AUTOSAR XML (schema 00047)
# (C) 2021 HYUNDAI AUTOEVER Corp.
package /Csm/ClientServerInterfaces
  13 x client server interface, all with is-service=true:
    CallbackNotification  # Interface for the callback notification.
      operation CallbackNotification  # Notifies the application with a return value that the job has finished.
        arg result: type=Csm_ResultType, direction=IN  # Return value that shall be returned to the application
    CsmDecryptAES_ECB_DecryptAES_ECB  # Synchronous processing interface to execute the decryption.
      operation Decrypt: possible-error=[CsmDecryptAES_ECB_DecryptAES_ECB/CSM_E_BUSY, CsmDecryptAES_ECB_DecryptAES_ECB/CSM_E_KEY_EMPTY, CsmDecryptAES_ECB_DecryptAES_ECB/CSM_E_KEY_NOT_VALID, CsmDecryptAES_ECB_DecryptAES_ECB/CSM_E_KEY_SIZE_MISMATCH, CsmDecryptAES_ECB_DecryptAES_ECB/CSM_E_SMALL_BUFFER, CsmDecryptAES_ECB_DecryptAES_ECB/E_NOT_OK, CsmDecryptAES_ECB_DecryptAES_ECB/E_OK]  # Streaming approach of the decryption.
        5 x arg:
          mode: type=Crypto_OperationModeType, direction=IN  # indicates which operation mode(s) to perform
          dataBuffer: type=Csm_ConstDataPtr, direction=IN  # Contains the data to be decrypted.
          dataLength: type=uint32, direction=IN  # Contains the length in bytes of the data to be decrypted.
          resultBuffer: type=uint8, direction=OUT  # Contains the data of the decrypted plaintext.
          resultLength: type=uint32, direction=INOUT  # Contains the length in bytes of the decrypted plaintext.
      7 x error:
        CSM_E_BUSY: error-code=2  # Request failed, service is still busy.
        CSM_E_KEY_EMPTY: error-code=13  # The service request failed because of uninitialized source key element.
        CSM_E_KEY_NOT_VALID: error-code=9  # Request failed, the key is not valid.
        CSM_E_KEY_SIZE_MISMATCH: error-code=10  # Request failed because the key element is not partially accessible and the provided key element length is too short or too long for that key element.
        CSM_E_SMALL_BUFFER: error-code=3  # The provided buffer is too small to store the result.
        E_NOT_OK: error-code=1  # Operation failed
        E_OK: error-code=0  # Operation successful
    CsmEncryptAES_ECB_EncryptAES_ECB  # Synchronous processing interface to execute the encryption.
      operation Encrypt: possible-error=[CsmEncryptAES_ECB_EncryptAES_ECB/CSM_E_BUSY, CsmEncryptAES_ECB_EncryptAES_ECB/CSM_E_KEY_EMPTY, CsmEncryptAES_ECB_EncryptAES_ECB/CSM_E_KEY_NOT_VALID, CsmEncryptAES_ECB_EncryptAES_ECB/CSM_E_KEY_SIZE_MISMATCH, CsmEncryptAES_ECB_EncryptAES_ECB/CSM_E_SMALL_BUFFER, CsmEncryptAES_ECB_EncryptAES_ECB/E_NOT_OK, CsmEncryptAES_ECB_EncryptAES_ECB/E_OK]  # Encrypts the given data and store the ciphertext in the memory location pointed by the result pointer.
        5 x arg:
          mode: type=Crypto_OperationModeType, direction=IN  # indicates which operation mode(s) to perform
          dataBuffer: type=Csm_ConstDataPtr, direction=IN  # Contains the data to be encrypted.
          dataLength: type=uint32, direction=IN  # Contains the length in bytes of the data to be encrypted.
          result: type=uint8, direction=OUT  # Contains the data of the cipher.
          resultLength: type=uint32, direction=INOUT  # Contains the length in bytes of the cipher.
      7 x error:
        CSM_E_BUSY: error-code=2  # Request failed, service is still busy.
        CSM_E_KEY_EMPTY: error-code=13  # The service request failed because of uninitialized source key element.
        CSM_E_KEY_NOT_VALID: error-code=9  # Request failed, the key is not valid.
        CSM_E_KEY_SIZE_MISMATCH: error-code=10  # Request failed because the key element is not partially accessible and the provided key element length is too short or too long for that key element.
        CSM_E_SMALL_BUFFER: error-code=3  # The provided buffer is too small to store the result.
        E_NOT_OK: error-code=1  # Operation failed
        E_OK: error-code=0  # Operation successful
    CsmHash_CsmHashConfig  # Synchronous processing interface to execute the hash calculation.
      operation Hash: possible-error=[CsmHash_CsmHashConfig/CSM_E_BUSY, CsmHash_CsmHashConfig/CSM_E_SMALL_BUFFER, CsmHash_CsmHashConfig/E_NOT_OK, CsmHash_CsmHashConfig/E_OK]  # Streaming approach of the hash calculation.
        5 x arg:
          mode: type=Crypto_OperationModeType, direction=IN  # indicates which operation mode(s) to perform
          dataBuffer: type=Csm_ConstDataPtr, direction=IN  # Contains the data to be hashed.
          dataLength: type=uint32, direction=IN  # Contains the length in bytes of the data to be hashed.
          resultBuffer: type=uint8, direction=OUT  # Contains the data of the hash.
          resultLength: type=uint32, direction=INOUT  # Contains the length in bytes of the hash.
      4 x error:
        CSM_E_BUSY: error-code=2  # Request failed, service is still busy.
        CSM_E_SMALL_BUFFER: error-code=3  # The provided buffer is too small to store the result.
        E_NOT_OK: error-code=1  # Operation failed
        E_OK: error-code=0  # Operation successful
    CsmKeyManagement_Dummy  # Interface to execute the key management functions.
      11 x operation:
        KeyCopy: possible-error=[CsmKeyManagement_Dummy/CSM_E_BUSY, CsmKeyManagement_Dummy/CSM_E_KEY_EMPTY, CsmKeyManagement_Dummy/CSM_E_KEY_NOT_AVAILABLE, CsmKeyManagement_Dummy/CSM_E_KEY_READ_FAIL, CsmKeyManagement_Dummy/CSM_E_KEY_SIZE_MISMATCH, CsmKeyManagement_Dummy/CSM_E_KEY_WRITE_FAIL, CsmKeyManagement_Dummy/E_NOT_OK, CsmKeyManagement_Dummy/E_OK]  # This function shall copy all key elements from the source key to a target key.
          arg targetKeyId: type=uint32, direction=IN  # Holds the identifier of the key whose key element shall be the destination element.
        KeyDerive: possible-error=[CsmKeyManagement_Dummy/CSM_E_BUSY, CsmKeyManagement_Dummy/CSM_E_KEY_EMPTY, CsmKeyManagement_Dummy/CSM_E_KEY_READ_FAIL, CsmKeyManagement_Dummy/CSM_E_KEY_SIZE_MISMATCH, CsmKeyManagement_Dummy/CSM_E_KEY_WRITE_FAIL, CsmKeyManagement_Dummy/E_NOT_OK, CsmKeyManagement_Dummy/E_OK]  # Derives a new key by using the key elements in the given key. The given key contains the key elements for the password and salt. The derived key is stored in the key element with the id 1 of the key identified by targetCryptoKeyId.
          arg targetKeyId: type=uint32, direction=IN  # Holds the identifier of the key which is used to store the derived key.
        KeyElementCopy: possible-error=[CsmKeyManagement_Dummy/CSM_E_BUSY, CsmKeyManagement_Dummy/CSM_E_KEY_EMPTY, CsmKeyManagement_Dummy/CSM_E_KEY_NOT_AVAILABLE, CsmKeyManagement_Dummy/CSM_E_KEY_READ_FAIL, CsmKeyManagement_Dummy/CSM_E_KEY_SIZE_MISMATCH, CsmKeyManagement_Dummy/CSM_E_KEY_WRITE_FAIL, CsmKeyManagement_Dummy/E_NOT_OK, CsmKeyManagement_Dummy/E_OK]  # This function shall copy a key elements from one key to a target key
          arg keyElementId: type=uint32, direction=IN  # Holds the identifier of the key element which shall be the source for the copy operation.
          arg targetKeyId: type=uint32, direction=IN  # Holds the identifier of the key whose key element shall be the destination element.
          arg targetKeyElementId: type=uint32, direction=IN  # Holds the identifier of the key element which shall be the destination for the copy operation.
        KeyElementCopyPartial: possible-error=[CsmKeyManagement_Dummy/CSM_E_BUSY, CsmKeyManagement_Dummy/CSM_E_KEY_EMPTY, CsmKeyManagement_Dummy/CSM_E_KEY_NOT_AVAILABLE, CsmKeyManagement_Dummy/CSM_E_KEY_READ_FAIL, CsmKeyManagement_Dummy/CSM_E_KEY_SIZE_MISMATCH, CsmKeyManagement_Dummy/CSM_E_KEY_WRITE_FAIL, CsmKeyManagement_Dummy/E_NOT_OK, CsmKeyManagement_Dummy/E_OK]  # This function shall copy parts of a a key elements from one key to parts of a target key element of a target key.
          6 x arg, all with type=uint32, direction=IN:
            keyElementId  # Holds the identifier of the key element which shall be the source for the copy operation.
            keyElementSourceOffset  # This is the offset of the source key element indicating the start index of the copy operation.
            keyElementTargetOffset  # This is the offset of the destination key element indicating the start index of the copy operation.
            keyElementCopyLength  # Specifies the number of bytes that shall be copied.
            targetKeyId  # Holds the identifier of the key whose key element shall be the destination element.
            targetKeyElementId  # Holds the identifier of the key element which shall be the destination for the copy operation.
        KeyElementGet: possible-error=[CsmKeyManagement_Dummy/CSM_E_BUSY, CsmKeyManagement_Dummy/CSM_E_KEY_EMPTY, CsmKeyManagement_Dummy/CSM_E_KEY_NOT_AVAILABLE, CsmKeyManagement_Dummy/CSM_E_KEY_READ_FAIL, CsmKeyManagement_Dummy/CSM_E_SMALL_BUFFER, CsmKeyManagement_Dummy/E_NOT_OK, CsmKeyManagement_Dummy/E_OK]  # Retrieves the key element bytes from a specific key element of the key and stores the key element in the provided buffer.
          arg keyElementId: type=uint32, direction=IN  # Holds the identifier of the key element to be read.
          arg keyPtr: type=uint8, direction=OUT  # Holds the data to the key element bytes to be written.
          arg keyLength: type=uint32, direction=INOUT  # Contains the number of key element bytes.
        KeyElementSet: possible-error=[CsmKeyManagement_Dummy/CSM_E_BUSY, CsmKeyManagement_Dummy/CSM_E_KEY_NOT_AVAILABLE, CsmKeyManagement_Dummy/CSM_E_KEY_SIZE_MISMATCH, CsmKeyManagement_Dummy/CSM_E_KEY_WRITE_FAIL, CsmKeyManagement_Dummy/E_NOT_OK, CsmKeyManagement_Dummy/E_OK]  # Sets the given key element bytes to the key.
          arg keyElementId: type=uint32, direction=IN  # Holds the identifier of the key element to be written.
          arg keyPtr: type=Csm_ConstDataPtr, direction=IN  # Holds the data to the key element bytes to be processed.
          arg keyLength: type=uint32, direction=IN  # Contains the number of key element bytes.
        KeyExchangeCalcPubVal: possible-error=[CsmKeyManagement_Dummy/CSM_E_BUSY, CsmKeyManagement_Dummy/CSM_E_KEY_EMPTY, CsmKeyManagement_Dummy/CSM_E_SMALL_BUFFER, CsmKeyManagement_Dummy/E_NOT_OK, CsmKeyManagement_Dummy/E_OK]  # Calculates the public value of the current user for the key exchange and stores the public key in the provided buffer
          arg publicValuePtr: type=uint8, direction=OUT  # Holds a pointer to the memory location in which the public value length in bytes is stored. On calling this function, this parameter shall contain the size of the buffer in bytes provided by publicValuePtr. When the request has finished, the actual length of the returned value shall be stored.
          arg publicValueLengthPtr: type=uint32, direction=INOUT  # Contains the pointer to the data where the public value shall be stored.
        KeyExchangeCalcSecret: possible-error=[CsmKeyManagement_Dummy/CSM_E_BUSY, CsmKeyManagement_Dummy/CSM_E_KEY_EMPTY, CsmKeyManagement_Dummy/CSM_E_SMALL_BUFFER, CsmKeyManagement_Dummy/E_NOT_OK, CsmKeyManagement_Dummy/E_OK]  # Calculates the shared secret key for the key exchange with the key material of the key identified by the keyId and the partner public key. The shared secret key is stored as a key element in the same key.
          arg partnerPublicValuePtr: type=Csm_ConstDataPtr, direction=IN  # Holds the pointer to the memory location containing the partner's public value
          arg partnerPublicValueLength: type=uint32, direction=IN  # Contains the number of bytes of the partner pulic value
        KeyGenerate: possible-error=[CsmKeyManagement_Dummy/CSM_E_BUSY, CsmKeyManagement_Dummy/CSM_E_KEY_EMPTY, CsmKeyManagement_Dummy/E_NOT_OK, CsmKeyManagement_Dummy/E_OK]  # Generates new key material and store it in the key identified by keyId.
        KeySetValid: possible-error=[CsmKeyManagement_Dummy/CSM_E_BUSY, CsmKeyManagement_Dummy/E_NOT_OK, CsmKeyManagement_Dummy/E_OK]  # Sets the given key element bytes to the key.
        RandomSeed: possible-error=[CsmKeyManagement_Dummy/CSM_E_BUSY, CsmKeyManagement_Dummy/E_NOT_OK, CsmKeyManagement_Dummy/E_OK]  # Feeds the key element CRYPTO_KE_RANDOM_SEED with a random seed.
          arg seedPtr: type=Csm_ConstDataPtr, direction=IN  # Holds the data which shall be used for the random seed initialization.
          arg seedLength: type=uint32, direction=IN  # Contains the length of the seed in bytes.
      9 x error:
        CSM_E_BUSY: error-code=2  # Request failed, service is still busy.
        CSM_E_KEY_EMPTY: error-code=13  # The service request failed because of uninitialized source key element.
        CSM_E_KEY_NOT_AVAILABLE: error-code=8  # The service request failed because the key is not available.
        CSM_E_KEY_READ_FAIL: error-code=6  # The service request failed because read access was denied.
        CSM_E_KEY_SIZE_MISMATCH: error-code=10  # Request failed because the key element is not partially accessible and the provided key element length is too short or too long for that key element.
        CSM_E_KEY_WRITE_FAIL: error-code=7  # The service request failed because write access was denied.
        CSM_E_SMALL_BUFFER: error-code=3  # The provided buffer is too small to store the result.
        E_NOT_OK: error-code=1  # Operation failed
        E_OK: error-code=0  # Operation successful
    CsmKeyManagement_PBKDF2_Extracted_Key  # Interface to execute the key management functions.
      11 x operation:
        KeyCopy: possible-error=[CsmKeyManagement_PBKDF2_Extracted_Key/CSM_E_BUSY, CsmKeyManagement_PBKDF2_Extracted_Key/CSM_E_KEY_EMPTY, CsmKeyManagement_PBKDF2_Extracted_Key/CSM_E_KEY_NOT_AVAILABLE, CsmKeyManagement_PBKDF2_Extracted_Key/CSM_E_KEY_READ_FAIL, CsmKeyManagement_PBKDF2_Extracted_Key/CSM_E_KEY_SIZE_MISMATCH, CsmKeyManagement_PBKDF2_Extracted_Key/CSM_E_KEY_WRITE_FAIL, CsmKeyManagement_PBKDF2_Extracted_Key/E_NOT_OK, CsmKeyManagement_PBKDF2_Extracted_Key/E_OK]  # This function shall copy all key elements from the source key to a target key.
          arg targetKeyId: type=uint32, direction=IN  # Holds the identifier of the key whose key element shall be the destination element.
        KeyDerive: possible-error=[CsmKeyManagement_PBKDF2_Extracted_Key/CSM_E_BUSY, CsmKeyManagement_PBKDF2_Extracted_Key/CSM_E_KEY_EMPTY, CsmKeyManagement_PBKDF2_Extracted_Key/CSM_E_KEY_READ_FAIL, CsmKeyManagement_PBKDF2_Extracted_Key/CSM_E_KEY_SIZE_MISMATCH, CsmKeyManagement_PBKDF2_Extracted_Key/CSM_E_KEY_WRITE_FAIL, CsmKeyManagement_PBKDF2_Extracted_Key/E_NOT_OK, CsmKeyManagement_PBKDF2_Extracted_Key/E_OK]  # Derives a new key by using the key elements in the given key. The given key contains the key elements for the password and salt. The derived key is stored in the key element with the id 1 of the key identified by targetCryptoKeyId.
          arg targetKeyId: type=uint32, direction=IN  # Holds the identifier of the key which is used to store the derived key.
        KeyElementCopy: possible-error=[CsmKeyManagement_PBKDF2_Extracted_Key/CSM_E_BUSY, CsmKeyManagement_PBKDF2_Extracted_Key/CSM_E_KEY_EMPTY, CsmKeyManagement_PBKDF2_Extracted_Key/CSM_E_KEY_NOT_AVAILABLE, CsmKeyManagement_PBKDF2_Extracted_Key/CSM_E_KEY_READ_FAIL, CsmKeyManagement_PBKDF2_Extracted_Key/CSM_E_KEY_SIZE_MISMATCH, CsmKeyManagement_PBKDF2_Extracted_Key/CSM_E_KEY_WRITE_FAIL, CsmKeyManagement_PBKDF2_Extracted_Key/E_NOT_OK, CsmKeyManagement_PBKDF2_Extracted_Key/E_OK]  # This function shall copy a key elements from one key to a target key
          arg keyElementId: type=uint32, direction=IN  # Holds the identifier of the key element which shall be the source for the copy operation.
          arg targetKeyId: type=uint32, direction=IN  # Holds the identifier of the key whose key element shall be the destination element.
          arg targetKeyElementId: type=uint32, direction=IN  # Holds the identifier of the key element which shall be the destination for the copy operation.
        KeyElementCopyPartial: possible-error=[CsmKeyManagement_PBKDF2_Extracted_Key/CSM_E_BUSY, CsmKeyManagement_PBKDF2_Extracted_Key/CSM_E_KEY_EMPTY, CsmKeyManagement_PBKDF2_Extracted_Key/CSM_E_KEY_NOT_AVAILABLE, CsmKeyManagement_PBKDF2_Extracted_Key/CSM_E_KEY_READ_FAIL, CsmKeyManagement_PBKDF2_Extracted_Key/CSM_E_KEY_SIZE_MISMATCH, CsmKeyManagement_PBKDF2_Extracted_Key/CSM_E_KEY_WRITE_FAIL, CsmKeyManagement_PBKDF2_Extracted_Key/E_NOT_OK, CsmKeyManagement_PBKDF2_Extracted_Key/E_OK]  # This function shall copy parts of a a key elements from one key to parts of a target key element of a target key.
          6 x arg, all with type=uint32, direction=IN:
            keyElementId  # Holds the identifier of the key element which shall be the source for the copy operation.
            keyElementSourceOffset  # This is the offset of the source key element indicating the start index of the copy operation.
            keyElementTargetOffset  # This is the offset of the destination key element indicating the start index of the copy operation.
            keyElementCopyLength  # Specifies the number of bytes that shall be copied.
            targetKeyId  # Holds the identifier of the key whose key element shall be the destination element.
            targetKeyElementId  # Holds the identifier of the key element which shall be the destination for the copy operation.
        KeyElementGet: possible-error=[CsmKeyManagement_PBKDF2_Extracted_Key/CSM_E_BUSY, CsmKeyManagement_PBKDF2_Extracted_Key/CSM_E_KEY_EMPTY, CsmKeyManagement_PBKDF2_Extracted_Key/CSM_E_KEY_NOT_AVAILABLE, CsmKeyManagement_PBKDF2_Extracted_Key/CSM_E_KEY_READ_FAIL, CsmKeyManagement_PBKDF2_Extracted_Key/CSM_E_SMALL_BUFFER, CsmKeyManagement_PBKDF2_Extracted_Key/E_NOT_OK, CsmKeyManagement_PBKDF2_Extracted_Key/E_OK]  # Retrieves the key element bytes from a specific key element of the key and stores the key element in the provided buffer.
          arg keyElementId: type=uint32, direction=IN  # Holds the identifier of the key element to be read.
          arg keyPtr: type=uint8, direction=OUT  # Holds the data to the key element bytes to be written.
          arg keyLength: type=uint32, direction=INOUT  # Contains the number of key element bytes.
        KeyElementSet: possible-error=[CsmKeyManagement_PBKDF2_Extracted_Key/CSM_E_BUSY, CsmKeyManagement_PBKDF2_Extracted_Key/CSM_E_KEY_NOT_AVAILABLE, CsmKeyManagement_PBKDF2_Extracted_Key/CSM_E_KEY_SIZE_MISMATCH, CsmKeyManagement_PBKDF2_Extracted_Key/CSM_E_KEY_WRITE_FAIL, CsmKeyManagement_PBKDF2_Extracted_Key/E_NOT_OK, CsmKeyManagement_PBKDF2_Extracted_Key/E_OK]  # Sets the given key element bytes to the key.
          arg keyElementId: type=uint32, direction=IN  # Holds the identifier of the key element to be written.
          arg keyPtr: type=Csm_ConstDataPtr, direction=IN  # Holds the data to the key element bytes to be processed.
          arg keyLength: type=uint32, direction=IN  # Contains the number of key element bytes.
        KeyExchangeCalcPubVal: possible-error=[CsmKeyManagement_PBKDF2_Extracted_Key/CSM_E_BUSY, CsmKeyManagement_PBKDF2_Extracted_Key/CSM_E_KEY_EMPTY, CsmKeyManagement_PBKDF2_Extracted_Key/CSM_E_SMALL_BUFFER, CsmKeyManagement_PBKDF2_Extracted_Key/E_NOT_OK, CsmKeyManagement_PBKDF2_Extracted_Key/E_OK]  # Calculates the public value of the current user for the key exchange and stores the public key in the provided buffer
          arg publicValuePtr: type=uint8, direction=OUT  # Holds a pointer to the memory location in which the public value length in bytes is stored. On calling this function, this parameter shall contain the size of the buffer in bytes provided by publicValuePtr. When the request has finished, the actual length of the returned value shall be stored.
          arg publicValueLengthPtr: type=uint32, direction=INOUT  # Contains the pointer to the data where the public value shall be stored.
        KeyExchangeCalcSecret: possible-error=[CsmKeyManagement_PBKDF2_Extracted_Key/CSM_E_BUSY, CsmKeyManagement_PBKDF2_Extracted_Key/CSM_E_KEY_EMPTY, CsmKeyManagement_PBKDF2_Extracted_Key/CSM_E_SMALL_BUFFER, CsmKeyManagement_PBKDF2_Extracted_Key/E_NOT_OK, CsmKeyManagement_PBKDF2_Extracted_Key/E_OK]  # Calculates the shared secret key for the key exchange with the key material of the key identified by the keyId and the partner public key. The shared secret key is stored as a key element in the same key.
          arg partnerPublicValuePtr: type=Csm_ConstDataPtr, direction=IN  # Holds the pointer to the memory location containing the partner's public value
          arg partnerPublicValueLength: type=uint32, direction=IN  # Contains the number of bytes of the partner pulic value
        KeyGenerate: possible-error=[CsmKeyManagement_PBKDF2_Extracted_Key/CSM_E_BUSY, CsmKeyManagement_PBKDF2_Extracted_Key/CSM_E_KEY_EMPTY, CsmKeyManagement_PBKDF2_Extracted_Key/E_NOT_OK, CsmKeyManagement_PBKDF2_Extracted_Key/E_OK]  # Generates new key material and store it in the key identified by keyId.
        KeySetValid: possible-error=[CsmKeyManagement_PBKDF2_Extracted_Key/CSM_E_BUSY, CsmKeyManagement_PBKDF2_Extracted_Key/E_NOT_OK, CsmKeyManagement_PBKDF2_Extracted_Key/E_OK]  # Sets the given key element bytes to the key.
        RandomSeed: possible-error=[CsmKeyManagement_PBKDF2_Extracted_Key/CSM_E_BUSY, CsmKeyManagement_PBKDF2_Extracted_Key/E_NOT_OK, CsmKeyManagement_PBKDF2_Extracted_Key/E_OK]  # Feeds the key element CRYPTO_KE_RANDOM_SEED with a random seed.
          arg seedPtr: type=Csm_ConstDataPtr, direction=IN  # Holds the data which shall be used for the random seed initialization.
          arg seedLength: type=uint32, direction=IN  # Contains the length of the seed in bytes.
      9 x error:
        CSM_E_BUSY: error-code=2  # Request failed, service is still busy.
        CSM_E_KEY_EMPTY: error-code=13  # The service request failed because of uninitialized source key element.
        CSM_E_KEY_NOT_AVAILABLE: error-code=8  # The service request failed because the key is not available.
        CSM_E_KEY_READ_FAIL: error-code=6  # The service request failed because read access was denied.
        CSM_E_KEY_SIZE_MISMATCH: error-code=10  # Request failed because the key element is not partially accessible and the provided key element length is too short or too long for that key element.
        CSM_E_KEY_WRITE_FAIL: error-code=7  # The service request failed because write access was denied.
        CSM_E_SMALL_BUFFER: error-code=3  # The provided buffer is too small to store the result.
        E_NOT_OK: error-code=1  # Operation failed
        E_OK: error-code=0  # Operation successful
    CsmKeyManagement_PBKDF2_Source_Key  # Interface to execute the key management functions.
      11 x operation:
        KeyCopy: possible-error=[CsmKeyManagement_PBKDF2_Source_Key/CSM_E_BUSY, CsmKeyManagement_PBKDF2_Source_Key/CSM_E_KEY_EMPTY, CsmKeyManagement_PBKDF2_Source_Key/CSM_E_KEY_NOT_AVAILABLE, CsmKeyManagement_PBKDF2_Source_Key/CSM_E_KEY_READ_FAIL, CsmKeyManagement_PBKDF2_Source_Key/CSM_E_KEY_SIZE_MISMATCH, CsmKeyManagement_PBKDF2_Source_Key/CSM_E_KEY_WRITE_FAIL, CsmKeyManagement_PBKDF2_Source_Key/E_NOT_OK, CsmKeyManagement_PBKDF2_Source_Key/E_OK]  # This function shall copy all key elements from the source key to a target key.
          arg targetKeyId: type=uint32, direction=IN  # Holds the identifier of the key whose key element shall be the destination element.
        KeyDerive: possible-error=[CsmKeyManagement_PBKDF2_Source_Key/CSM_E_BUSY, CsmKeyManagement_PBKDF2_Source_Key/CSM_E_KEY_EMPTY, CsmKeyManagement_PBKDF2_Source_Key/CSM_E_KEY_READ_FAIL, CsmKeyManagement_PBKDF2_Source_Key/CSM_E_KEY_SIZE_MISMATCH, CsmKeyManagement_PBKDF2_Source_Key/CSM_E_KEY_WRITE_FAIL, CsmKeyManagement_PBKDF2_Source_Key/E_NOT_OK, CsmKeyManagement_PBKDF2_Source_Key/E_OK]  # Derives a new key by using the key elements in the given key. The given key contains the key elements for the password and salt. The derived key is stored in the key element with the id 1 of the key identified by targetCryptoKeyId.
          arg targetKeyId: type=uint32, direction=IN  # Holds the identifier of the key which is used to store the derived key.
        KeyElementCopy: possible-error=[CsmKeyManagement_PBKDF2_Source_Key/CSM_E_BUSY, CsmKeyManagement_PBKDF2_Source_Key/CSM_E_KEY_EMPTY, CsmKeyManagement_PBKDF2_Source_Key/CSM_E_KEY_NOT_AVAILABLE, CsmKeyManagement_PBKDF2_Source_Key/CSM_E_KEY_READ_FAIL, CsmKeyManagement_PBKDF2_Source_Key/CSM_E_KEY_SIZE_MISMATCH, CsmKeyManagement_PBKDF2_Source_Key/CSM_E_KEY_WRITE_FAIL, CsmKeyManagement_PBKDF2_Source_Key/E_NOT_OK, CsmKeyManagement_PBKDF2_Source_Key/E_OK]  # This function shall copy a key elements from one key to a target key
          arg keyElementId: type=uint32, direction=IN  # Holds the identifier of the key element which shall be the source for the copy operation.
          arg targetKeyId: type=uint32, direction=IN  # Holds the identifier of the key whose key element shall be the destination element.
          arg targetKeyElementId: type=uint32, direction=IN  # Holds the identifier of the key element which shall be the destination for the copy operation.
        KeyElementCopyPartial: possible-error=[CsmKeyManagement_PBKDF2_Source_Key/CSM_E_BUSY, CsmKeyManagement_PBKDF2_Source_Key/CSM_E_KEY_EMPTY, CsmKeyManagement_PBKDF2_Source_Key/CSM_E_KEY_NOT_AVAILABLE, CsmKeyManagement_PBKDF2_Source_Key/CSM_E_KEY_READ_FAIL, CsmKeyManagement_PBKDF2_Source_Key/CSM_E_KEY_SIZE_MISMATCH, CsmKeyManagement_PBKDF2_Source_Key/CSM_E_KEY_WRITE_FAIL, CsmKeyManagement_PBKDF2_Source_Key/E_NOT_OK, CsmKeyManagement_PBKDF2_Source_Key/E_OK]  # This function shall copy parts of a a key elements from one key to parts of a target key element of a target key.
          6 x arg, all with type=uint32, direction=IN:
            keyElementId  # Holds the identifier of the key element which shall be the source for the copy operation.
            keyElementSourceOffset  # This is the offset of the source key element indicating the start index of the copy operation.
            keyElementTargetOffset  # This is the offset of the destination key element indicating the start index of the copy operation.
            keyElementCopyLength  # Specifies the number of bytes that shall be copied.
            targetKeyId  # Holds the identifier of the key whose key element shall be the destination element.
            targetKeyElementId  # Holds the identifier of the key element which shall be the destination for the copy operation.
        KeyElementGet: possible-error=[CsmKeyManagement_PBKDF2_Source_Key/CSM_E_BUSY, CsmKeyManagement_PBKDF2_Source_Key/CSM_E_KEY_EMPTY, CsmKeyManagement_PBKDF2_Source_Key/CSM_E_KEY_NOT_AVAILABLE, CsmKeyManagement_PBKDF2_Source_Key/CSM_E_KEY_READ_FAIL, CsmKeyManagement_PBKDF2_Source_Key/CSM_E_SMALL_BUFFER, CsmKeyManagement_PBKDF2_Source_Key/E_NOT_OK, CsmKeyManagement_PBKDF2_Source_Key/E_OK]  # Retrieves the key element bytes from a specific key element of the key and stores the key element in the provided buffer.
          arg keyElementId: type=uint32, direction=IN  # Holds the identifier of the key element to be read.
          arg keyPtr: type=uint8, direction=OUT  # Holds the data to the key element bytes to be written.
          arg keyLength: type=uint32, direction=INOUT  # Contains the number of key element bytes.
        KeyElementSet: possible-error=[CsmKeyManagement_PBKDF2_Source_Key/CSM_E_BUSY, CsmKeyManagement_PBKDF2_Source_Key/CSM_E_KEY_NOT_AVAILABLE, CsmKeyManagement_PBKDF2_Source_Key/CSM_E_KEY_SIZE_MISMATCH, CsmKeyManagement_PBKDF2_Source_Key/CSM_E_KEY_WRITE_FAIL, CsmKeyManagement_PBKDF2_Source_Key/E_NOT_OK, CsmKeyManagement_PBKDF2_Source_Key/E_OK]  # Sets the given key element bytes to the key.
          arg keyElementId: type=uint32, direction=IN  # Holds the identifier of the key element to be written.
          arg keyPtr: type=Csm_ConstDataPtr, direction=IN  # Holds the data to the key element bytes to be processed.
          arg keyLength: type=uint32, direction=IN  # Contains the number of key element bytes.
        KeyExchangeCalcPubVal: possible-error=[CsmKeyManagement_PBKDF2_Source_Key/CSM_E_BUSY, CsmKeyManagement_PBKDF2_Source_Key/CSM_E_KEY_EMPTY, CsmKeyManagement_PBKDF2_Source_Key/CSM_E_SMALL_BUFFER, CsmKeyManagement_PBKDF2_Source_Key/E_NOT_OK, CsmKeyManagement_PBKDF2_Source_Key/E_OK]  # Calculates the public value of the current user for the key exchange and stores the public key in the provided buffer
          arg publicValuePtr: type=uint8, direction=OUT  # Holds a pointer to the memory location in which the public value length in bytes is stored. On calling this function, this parameter shall contain the size of the buffer in bytes provided by publicValuePtr. When the request has finished, the actual length of the returned value shall be stored.
          arg publicValueLengthPtr: type=uint32, direction=INOUT  # Contains the pointer to the data where the public value shall be stored.
        KeyExchangeCalcSecret: possible-error=[CsmKeyManagement_PBKDF2_Source_Key/CSM_E_BUSY, CsmKeyManagement_PBKDF2_Source_Key/CSM_E_KEY_EMPTY, CsmKeyManagement_PBKDF2_Source_Key/CSM_E_SMALL_BUFFER, CsmKeyManagement_PBKDF2_Source_Key/E_NOT_OK, CsmKeyManagement_PBKDF2_Source_Key/E_OK]  # Calculates the shared secret key for the key exchange with the key material of the key identified by the keyId and the partner public key. The shared secret key is stored as a key element in the same key.
          arg partnerPublicValuePtr: type=Csm_ConstDataPtr, direction=IN  # Holds the pointer to the memory location containing the partner's public value
          arg partnerPublicValueLength: type=uint32, direction=IN  # Contains the number of bytes of the partner pulic value
        KeyGenerate: possible-error=[CsmKeyManagement_PBKDF2_Source_Key/CSM_E_BUSY, CsmKeyManagement_PBKDF2_Source_Key/CSM_E_KEY_EMPTY, CsmKeyManagement_PBKDF2_Source_Key/E_NOT_OK, CsmKeyManagement_PBKDF2_Source_Key/E_OK]  # Generates new key material and store it in the key identified by keyId.
        KeySetValid: possible-error=[CsmKeyManagement_PBKDF2_Source_Key/CSM_E_BUSY, CsmKeyManagement_PBKDF2_Source_Key/E_NOT_OK, CsmKeyManagement_PBKDF2_Source_Key/E_OK]  # Sets the given key element bytes to the key.
        RandomSeed: possible-error=[CsmKeyManagement_PBKDF2_Source_Key/CSM_E_BUSY, CsmKeyManagement_PBKDF2_Source_Key/E_NOT_OK, CsmKeyManagement_PBKDF2_Source_Key/E_OK]  # Feeds the key element CRYPTO_KE_RANDOM_SEED with a random seed.
          arg seedPtr: type=Csm_ConstDataPtr, direction=IN  # Holds the data which shall be used for the random seed initialization.
          arg seedLength: type=uint32, direction=IN  # Contains the length of the seed in bytes.
      9 x error:
        CSM_E_BUSY: error-code=2  # Request failed, service is still busy.
        CSM_E_KEY_EMPTY: error-code=13  # The service request failed because of uninitialized source key element.
        CSM_E_KEY_NOT_AVAILABLE: error-code=8  # The service request failed because the key is not available.
        CSM_E_KEY_READ_FAIL: error-code=6  # The service request failed because read access was denied.
        CSM_E_KEY_SIZE_MISMATCH: error-code=10  # Request failed because the key element is not partially accessible and the provided key element length is too short or too long for that key element.
        CSM_E_KEY_WRITE_FAIL: error-code=7  # The service request failed because write access was denied.
        CSM_E_SMALL_BUFFER: error-code=3  # The provided buffer is too small to store the result.
        E_NOT_OK: error-code=1  # Operation failed
        E_OK: error-code=0  # Operation successful
    CsmKeyManagement_PBKDF2_Target_Key  # Interface to execute the key management functions.
      11 x operation:
        KeyCopy: possible-error=[CsmKeyManagement_PBKDF2_Target_Key/CSM_E_BUSY, CsmKeyManagement_PBKDF2_Target_Key/CSM_E_KEY_EMPTY, CsmKeyManagement_PBKDF2_Target_Key/CSM_E_KEY_NOT_AVAILABLE, CsmKeyManagement_PBKDF2_Target_Key/CSM_E_KEY_READ_FAIL, CsmKeyManagement_PBKDF2_Target_Key/CSM_E_KEY_SIZE_MISMATCH, CsmKeyManagement_PBKDF2_Target_Key/CSM_E_KEY_WRITE_FAIL, CsmKeyManagement_PBKDF2_Target_Key/E_NOT_OK, CsmKeyManagement_PBKDF2_Target_Key/E_OK]  # This function shall copy all key elements from the source key to a target key.
          arg targetKeyId: type=uint32, direction=IN  # Holds the identifier of the key whose key element shall be the destination element.
        KeyDerive: possible-error=[CsmKeyManagement_PBKDF2_Target_Key/CSM_E_BUSY, CsmKeyManagement_PBKDF2_Target_Key/CSM_E_KEY_EMPTY, CsmKeyManagement_PBKDF2_Target_Key/CSM_E_KEY_READ_FAIL, CsmKeyManagement_PBKDF2_Target_Key/CSM_E_KEY_SIZE_MISMATCH, CsmKeyManagement_PBKDF2_Target_Key/CSM_E_KEY_WRITE_FAIL, CsmKeyManagement_PBKDF2_Target_Key/E_NOT_OK, CsmKeyManagement_PBKDF2_Target_Key/E_OK]  # Derives a new key by using the key elements in the given key. The given key contains the key elements for the password and salt. The derived key is stored in the key element with the id 1 of the key identified by targetCryptoKeyId.
          arg targetKeyId: type=uint32, direction=IN  # Holds the identifier of the key which is used to store the derived key.
        KeyElementCopy: possible-error=[CsmKeyManagement_PBKDF2_Target_Key/CSM_E_BUSY, CsmKeyManagement_PBKDF2_Target_Key/CSM_E_KEY_EMPTY, CsmKeyManagement_PBKDF2_Target_Key/CSM_E_KEY_NOT_AVAILABLE, CsmKeyManagement_PBKDF2_Target_Key/CSM_E_KEY_READ_FAIL, CsmKeyManagement_PBKDF2_Target_Key/CSM_E_KEY_SIZE_MISMATCH, CsmKeyManagement_PBKDF2_Target_Key/CSM_E_KEY_WRITE_FAIL, CsmKeyManagement_PBKDF2_Target_Key/E_NOT_OK, CsmKeyManagement_PBKDF2_Target_Key/E_OK]  # This function shall copy a key elements from one key to a target key
          arg keyElementId: type=uint32, direction=IN  # Holds the identifier of the key element which shall be the source for the copy operation.
          arg targetKeyId: type=uint32, direction=IN  # Holds the identifier of the key whose key element shall be the destination element.
          arg targetKeyElementId: type=uint32, direction=IN  # Holds the identifier of the key element which shall be the destination for the copy operation.
        KeyElementCopyPartial: possible-error=[CsmKeyManagement_PBKDF2_Target_Key/CSM_E_BUSY, CsmKeyManagement_PBKDF2_Target_Key/CSM_E_KEY_EMPTY, CsmKeyManagement_PBKDF2_Target_Key/CSM_E_KEY_NOT_AVAILABLE, CsmKeyManagement_PBKDF2_Target_Key/CSM_E_KEY_READ_FAIL, CsmKeyManagement_PBKDF2_Target_Key/CSM_E_KEY_SIZE_MISMATCH, CsmKeyManagement_PBKDF2_Target_Key/CSM_E_KEY_WRITE_FAIL, CsmKeyManagement_PBKDF2_Target_Key/E_NOT_OK, CsmKeyManagement_PBKDF2_Target_Key/E_OK]  # This function shall copy parts of a a key elements from one key to parts of a target key element of a target key.
          6 x arg, all with type=uint32, direction=IN:
            keyElementId  # Holds the identifier of the key element which shall be the source for the copy operation.
            keyElementSourceOffset  # This is the offset of the source key element indicating the start index of the copy operation.
            keyElementTargetOffset  # This is the offset of the destination key element indicating the start index of the copy operation.
            keyElementCopyLength  # Specifies the number of bytes that shall be copied.
            targetKeyId  # Holds the identifier of the key whose key element shall be the destination element.
            targetKeyElementId  # Holds the identifier of the key element which shall be the destination for the copy operation.
        KeyElementGet: possible-error=[CsmKeyManagement_PBKDF2_Target_Key/CSM_E_BUSY, CsmKeyManagement_PBKDF2_Target_Key/CSM_E_KEY_EMPTY, CsmKeyManagement_PBKDF2_Target_Key/CSM_E_KEY_NOT_AVAILABLE, CsmKeyManagement_PBKDF2_Target_Key/CSM_E_KEY_READ_FAIL, CsmKeyManagement_PBKDF2_Target_Key/CSM_E_SMALL_BUFFER, CsmKeyManagement_PBKDF2_Target_Key/E_NOT_OK, CsmKeyManagement_PBKDF2_Target_Key/E_OK]  # Retrieves the key element bytes from a specific key element of the key and stores the key element in the provided buffer.
          arg keyElementId: type=uint32, direction=IN  # Holds the identifier of the key element to be read.
          arg keyPtr: type=uint8, direction=OUT  # Holds the data to the key element bytes to be written.
          arg keyLength: type=uint32, direction=INOUT  # Contains the number of key element bytes.
        KeyElementSet: possible-error=[CsmKeyManagement_PBKDF2_Target_Key/CSM_E_BUSY, CsmKeyManagement_PBKDF2_Target_Key/CSM_E_KEY_NOT_AVAILABLE, CsmKeyManagement_PBKDF2_Target_Key/CSM_E_KEY_SIZE_MISMATCH, CsmKeyManagement_PBKDF2_Target_Key/CSM_E_KEY_WRITE_FAIL, CsmKeyManagement_PBKDF2_Target_Key/E_NOT_OK, CsmKeyManagement_PBKDF2_Target_Key/E_OK]  # Sets the given key element bytes to the key.
          arg keyElementId: type=uint32, direction=IN  # Holds the identifier of the key element to be written.
          arg keyPtr: type=Csm_ConstDataPtr, direction=IN  # Holds the data to the key element bytes to be processed.
          arg keyLength: type=uint32, direction=IN  # Contains the number of key element bytes.
        KeyExchangeCalcPubVal: possible-error=[CsmKeyManagement_PBKDF2_Target_Key/CSM_E_BUSY, CsmKeyManagement_PBKDF2_Target_Key/CSM_E_KEY_EMPTY, CsmKeyManagement_PBKDF2_Target_Key/CSM_E_SMALL_BUFFER, CsmKeyManagement_PBKDF2_Target_Key/E_NOT_OK, CsmKeyManagement_PBKDF2_Target_Key/E_OK]  # Calculates the public value of the current user for the key exchange and stores the public key in the provided buffer
          arg publicValuePtr: type=uint8, direction=OUT  # Holds a pointer to the memory location in which the public value length in bytes is stored. On calling this function, this parameter shall contain the size of the buffer in bytes provided by publicValuePtr. When the request has finished, the actual length of the returned value shall be stored.
          arg publicValueLengthPtr: type=uint32, direction=INOUT  # Contains the pointer to the data where the public value shall be stored.
        KeyExchangeCalcSecret: possible-error=[CsmKeyManagement_PBKDF2_Target_Key/CSM_E_BUSY, CsmKeyManagement_PBKDF2_Target_Key/CSM_E_KEY_EMPTY, CsmKeyManagement_PBKDF2_Target_Key/CSM_E_SMALL_BUFFER, CsmKeyManagement_PBKDF2_Target_Key/E_NOT_OK, CsmKeyManagement_PBKDF2_Target_Key/E_OK]  # Calculates the shared secret key for the key exchange with the key material of the key identified by the keyId and the partner public key. The shared secret key is stored as a key element in the same key.
          arg partnerPublicValuePtr: type=Csm_ConstDataPtr, direction=IN  # Holds the pointer to the memory location containing the partner's public value
          arg partnerPublicValueLength: type=uint32, direction=IN  # Contains the number of bytes of the partner pulic value
        KeyGenerate: possible-error=[CsmKeyManagement_PBKDF2_Target_Key/CSM_E_BUSY, CsmKeyManagement_PBKDF2_Target_Key/CSM_E_KEY_EMPTY, CsmKeyManagement_PBKDF2_Target_Key/E_NOT_OK, CsmKeyManagement_PBKDF2_Target_Key/E_OK]  # Generates new key material and store it in the key identified by keyId.
        KeySetValid: possible-error=[CsmKeyManagement_PBKDF2_Target_Key/CSM_E_BUSY, CsmKeyManagement_PBKDF2_Target_Key/E_NOT_OK, CsmKeyManagement_PBKDF2_Target_Key/E_OK]  # Sets the given key element bytes to the key.
        RandomSeed: possible-error=[CsmKeyManagement_PBKDF2_Target_Key/CSM_E_BUSY, CsmKeyManagement_PBKDF2_Target_Key/E_NOT_OK, CsmKeyManagement_PBKDF2_Target_Key/E_OK]  # Feeds the key element CRYPTO_KE_RANDOM_SEED with a random seed.
          arg seedPtr: type=Csm_ConstDataPtr, direction=IN  # Holds the data which shall be used for the random seed initialization.
          arg seedLength: type=uint32, direction=IN  # Contains the length of the seed in bytes.
      9 x error:
        CSM_E_BUSY: error-code=2  # Request failed, service is still busy.
        CSM_E_KEY_EMPTY: error-code=13  # The service request failed because of uninitialized source key element.
        CSM_E_KEY_NOT_AVAILABLE: error-code=8  # The service request failed because the key is not available.
        CSM_E_KEY_READ_FAIL: error-code=6  # The service request failed because read access was denied.
        CSM_E_KEY_SIZE_MISMATCH: error-code=10  # Request failed because the key element is not partially accessible and the provided key element length is too short or too long for that key element.
        CSM_E_KEY_WRITE_FAIL: error-code=7  # The service request failed because write access was denied.
        CSM_E_SMALL_BUFFER: error-code=3  # The provided buffer is too small to store the result.
        E_NOT_OK: error-code=1  # Operation failed
        E_OK: error-code=0  # Operation successful
    CsmKeyManagement_RandomSeed_L9  # Interface to execute the key management functions.
      11 x operation:
        KeyCopy: possible-error=[CsmKeyManagement_RandomSeed_L9/CSM_E_BUSY, CsmKeyManagement_RandomSeed_L9/CSM_E_KEY_EMPTY, CsmKeyManagement_RandomSeed_L9/CSM_E_KEY_NOT_AVAILABLE, CsmKeyManagement_RandomSeed_L9/CSM_E_KEY_READ_FAIL, CsmKeyManagement_RandomSeed_L9/CSM_E_KEY_SIZE_MISMATCH, CsmKeyManagement_RandomSeed_L9/CSM_E_KEY_WRITE_FAIL, CsmKeyManagement_RandomSeed_L9/E_NOT_OK, CsmKeyManagement_RandomSeed_L9/E_OK]  # This function shall copy all key elements from the source key to a target key.
          arg targetKeyId: type=uint32, direction=IN  # Holds the identifier of the key whose key element shall be the destination element.
        KeyDerive: possible-error=[CsmKeyManagement_RandomSeed_L9/CSM_E_BUSY, CsmKeyManagement_RandomSeed_L9/CSM_E_KEY_EMPTY, CsmKeyManagement_RandomSeed_L9/CSM_E_KEY_READ_FAIL, CsmKeyManagement_RandomSeed_L9/CSM_E_KEY_SIZE_MISMATCH, CsmKeyManagement_RandomSeed_L9/CSM_E_KEY_WRITE_FAIL, CsmKeyManagement_RandomSeed_L9/E_NOT_OK, CsmKeyManagement_RandomSeed_L9/E_OK]  # Derives a new key by using the key elements in the given key. The given key contains the key elements for the password and salt. The derived key is stored in the key element with the id 1 of the key identified by targetCryptoKeyId.
          arg targetKeyId: type=uint32, direction=IN  # Holds the identifier of the key which is used to store the derived key.
        KeyElementCopy: possible-error=[CsmKeyManagement_RandomSeed_L9/CSM_E_BUSY, CsmKeyManagement_RandomSeed_L9/CSM_E_KEY_EMPTY, CsmKeyManagement_RandomSeed_L9/CSM_E_KEY_NOT_AVAILABLE, CsmKeyManagement_RandomSeed_L9/CSM_E_KEY_READ_FAIL, CsmKeyManagement_RandomSeed_L9/CSM_E_KEY_SIZE_MISMATCH, CsmKeyManagement_RandomSeed_L9/CSM_E_KEY_WRITE_FAIL, CsmKeyManagement_RandomSeed_L9/E_NOT_OK, CsmKeyManagement_RandomSeed_L9/E_OK]  # This function shall copy a key elements from one key to a target key
          arg keyElementId: type=uint32, direction=IN  # Holds the identifier of the key element which shall be the source for the copy operation.
          arg targetKeyId: type=uint32, direction=IN  # Holds the identifier of the key whose key element shall be the destination element.
          arg targetKeyElementId: type=uint32, direction=IN  # Holds the identifier of the key element which shall be the destination for the copy operation.
        KeyElementCopyPartial: possible-error=[CsmKeyManagement_RandomSeed_L9/CSM_E_BUSY, CsmKeyManagement_RandomSeed_L9/CSM_E_KEY_EMPTY, CsmKeyManagement_RandomSeed_L9/CSM_E_KEY_NOT_AVAILABLE, CsmKeyManagement_RandomSeed_L9/CSM_E_KEY_READ_FAIL, CsmKeyManagement_RandomSeed_L9/CSM_E_KEY_SIZE_MISMATCH, CsmKeyManagement_RandomSeed_L9/CSM_E_KEY_WRITE_FAIL, CsmKeyManagement_RandomSeed_L9/E_NOT_OK, CsmKeyManagement_RandomSeed_L9/E_OK]  # This function shall copy parts of a a key elements from one key to parts of a target key element of a target key.
          6 x arg, all with type=uint32, direction=IN:
            keyElementId  # Holds the identifier of the key element which shall be the source for the copy operation.
            keyElementSourceOffset  # This is the offset of the source key element indicating the start index of the copy operation.
            keyElementTargetOffset  # This is the offset of the destination key element indicating the start index of the copy operation.
            keyElementCopyLength  # Specifies the number of bytes that shall be copied.
            targetKeyId  # Holds the identifier of the key whose key element shall be the destination element.
            targetKeyElementId  # Holds the identifier of the key element which shall be the destination for the copy operation.
        KeyElementGet: possible-error=[CsmKeyManagement_RandomSeed_L9/CSM_E_BUSY, CsmKeyManagement_RandomSeed_L9/CSM_E_KEY_EMPTY, CsmKeyManagement_RandomSeed_L9/CSM_E_KEY_NOT_AVAILABLE, CsmKeyManagement_RandomSeed_L9/CSM_E_KEY_READ_FAIL, CsmKeyManagement_RandomSeed_L9/CSM_E_SMALL_BUFFER, CsmKeyManagement_RandomSeed_L9/E_NOT_OK, CsmKeyManagement_RandomSeed_L9/E_OK]  # Retrieves the key element bytes from a specific key element of the key and stores the key element in the provided buffer.
          arg keyElementId: type=uint32, direction=IN  # Holds the identifier of the key element to be read.
          arg keyPtr: type=uint8, direction=OUT  # Holds the data to the key element bytes to be written.
          arg keyLength: type=uint32, direction=INOUT  # Contains the number of key element bytes.
        KeyElementSet: possible-error=[CsmKeyManagement_RandomSeed_L9/CSM_E_BUSY, CsmKeyManagement_RandomSeed_L9/CSM_E_KEY_NOT_AVAILABLE, CsmKeyManagement_RandomSeed_L9/CSM_E_KEY_SIZE_MISMATCH, CsmKeyManagement_RandomSeed_L9/CSM_E_KEY_WRITE_FAIL, CsmKeyManagement_RandomSeed_L9/E_NOT_OK, CsmKeyManagement_RandomSeed_L9/E_OK]  # Sets the given key element bytes to the key.
          arg keyElementId: type=uint32, direction=IN  # Holds the identifier of the key element to be written.
          arg keyPtr: type=Csm_ConstDataPtr, direction=IN  # Holds the data to the key element bytes to be processed.
          arg keyLength: type=uint32, direction=IN  # Contains the number of key element bytes.
        KeyExchangeCalcPubVal: possible-error=[CsmKeyManagement_RandomSeed_L9/CSM_E_BUSY, CsmKeyManagement_RandomSeed_L9/CSM_E_KEY_EMPTY, CsmKeyManagement_RandomSeed_L9/CSM_E_SMALL_BUFFER, CsmKeyManagement_RandomSeed_L9/E_NOT_OK, CsmKeyManagement_RandomSeed_L9/E_OK]  # Calculates the public value of the current user for the key exchange and stores the public key in the provided buffer
          arg publicValuePtr: type=uint8, direction=OUT  # Holds a pointer to the memory location in which the public value length in bytes is stored. On calling this function, this parameter shall contain the size of the buffer in bytes provided by publicValuePtr. When the request has finished, the actual length of the returned value shall be stored.
          arg publicValueLengthPtr: type=uint32, direction=INOUT  # Contains the pointer to the data where the public value shall be stored.
        KeyExchangeCalcSecret: possible-error=[CsmKeyManagement_RandomSeed_L9/CSM_E_BUSY, CsmKeyManagement_RandomSeed_L9/CSM_E_KEY_EMPTY, CsmKeyManagement_RandomSeed_L9/CSM_E_SMALL_BUFFER, CsmKeyManagement_RandomSeed_L9/E_NOT_OK, CsmKeyManagement_RandomSeed_L9/E_OK]  # Calculates the shared secret key for the key exchange with the key material of the key identified by the keyId and the partner public key. The shared secret key is stored as a key element in the same key.
          arg partnerPublicValuePtr: type=Csm_ConstDataPtr, direction=IN  # Holds the pointer to the memory location containing the partner's public value
          arg partnerPublicValueLength: type=uint32, direction=IN  # Contains the number of bytes of the partner pulic value
        KeyGenerate: possible-error=[CsmKeyManagement_RandomSeed_L9/CSM_E_BUSY, CsmKeyManagement_RandomSeed_L9/CSM_E_KEY_EMPTY, CsmKeyManagement_RandomSeed_L9/E_NOT_OK, CsmKeyManagement_RandomSeed_L9/E_OK]  # Generates new key material and store it in the key identified by keyId.
        KeySetValid: possible-error=[CsmKeyManagement_RandomSeed_L9/CSM_E_BUSY, CsmKeyManagement_RandomSeed_L9/E_NOT_OK, CsmKeyManagement_RandomSeed_L9/E_OK]  # Sets the given key element bytes to the key.
        RandomSeed: possible-error=[CsmKeyManagement_RandomSeed_L9/CSM_E_BUSY, CsmKeyManagement_RandomSeed_L9/E_NOT_OK, CsmKeyManagement_RandomSeed_L9/E_OK]  # Feeds the key element CRYPTO_KE_RANDOM_SEED with a random seed.
          arg seedPtr: type=Csm_ConstDataPtr, direction=IN  # Holds the data which shall be used for the random seed initialization.
          arg seedLength: type=uint32, direction=IN  # Contains the length of the seed in bytes.
      9 x error:
        CSM_E_BUSY: error-code=2  # Request failed, service is still busy.
        CSM_E_KEY_EMPTY: error-code=13  # The service request failed because of uninitialized source key element.
        CSM_E_KEY_NOT_AVAILABLE: error-code=8  # The service request failed because the key is not available.
        CSM_E_KEY_READ_FAIL: error-code=6  # The service request failed because read access was denied.
        CSM_E_KEY_SIZE_MISMATCH: error-code=10  # Request failed because the key element is not partially accessible and the provided key element length is too short or too long for that key element.
        CSM_E_KEY_WRITE_FAIL: error-code=7  # The service request failed because write access was denied.
        CSM_E_SMALL_BUFFER: error-code=3  # The provided buffer is too small to store the result.
        E_NOT_OK: error-code=1  # Operation failed
        E_OK: error-code=0  # Operation successful
    CsmRandomGenerate_CsmRandomGenerateConfig  # Synchronous processing interface to execute the random number generation.
      operation RandomGenerate: possible-error=[CsmRandomGenerate_CsmRandomGenerateConfig/CSM_E_BUSY, CsmRandomGenerate_CsmRandomGenerateConfig/CSM_E_ENTROPY_EXHAUSTION, CsmRandomGenerate_CsmRandomGenerateConfig/E_NOT_OK, CsmRandomGenerate_CsmRandomGenerateConfig/E_OK]  # Synchronous processing interface to execute the random number generation.
        arg resultBuffer: type=uint8, direction=OUT  # Contains the random number
        arg resultLength: type=uint32, direction=INOUT  # Contains the length in bytes of the data of random number.
      4 x error:
        CSM_E_BUSY: error-code=2  # Request failed, service is still busy.
        CSM_E_ENTROPY_EXHAUSTION: error-code=4  # Request failed, entropy of random number generator is exhausted.
        E_NOT_OK: error-code=1  # Operation failed
        E_OK: error-code=0  # Operation successful
    CsmSha256HmacGenerate_CsmMacGenerateConfig  # Synchronous processing interface to execute the MAC generation.
      operation MacGenerate: possible-error=[CsmSha256HmacGenerate_CsmMacGenerateConfig/CSM_E_BUSY, CsmSha256HmacGenerate_CsmMacGenerateConfig/CSM_E_KEY_EMPTY, CsmSha256HmacGenerate_CsmMacGenerateConfig/CSM_E_KEY_NOT_VALID, CsmSha256HmacGenerate_CsmMacGenerateConfig/CSM_E_KEY_SIZE_MISMATCH, CsmSha256HmacGenerate_CsmMacGenerateConfig/CSM_E_SMALL_BUFFER, CsmSha256HmacGenerate_CsmMacGenerateConfig/E_NOT_OK, CsmSha256HmacGenerate_CsmMacGenerateConfig/E_OK]  # Uses the given data to perform a MAC generation and stores the MAC in the memory location pointed to by the MAC pointer.
        5 x arg:
          mode: type=Crypto_OperationModeType, direction=IN  # indicates which operation mode(s) to perform
          dataBuffer: type=Csm_ConstDataPtr, direction=IN  # Contains the data from which a MAC shall be generated of.
          dataLength: type=uint32, direction=IN  # Contains the length in bytes of the data from which a MAC shall be generated of.
          resultBuffer: type=uint8, direction=OUT  # Contains the data of the MAC.
          resultLength: type=uint32, direction=INOUT  # Contains the length in bytes of the MAC.
      7 x error:
        CSM_E_BUSY: error-code=2  # Request failed, service is still busy.
        CSM_E_KEY_EMPTY: error-code=13  # The service request failed because of uninitialized source key element.
        CSM_E_KEY_NOT_VALID: error-code=9  # Request failed, the key is not valid.
        CSM_E_KEY_SIZE_MISMATCH: error-code=10  # Request failed because the key element is not partially accessible and the provided key element length is too short or too long for that key element.
        CSM_E_SMALL_BUFFER: error-code=3  # The provided buffer is too small to store the result.
        E_NOT_OK: error-code=1  # Operation failed
        E_OK: error-code=0  # Operation successful
    CsmSha256HmacVerify_CsmMacVerifyConfig  # Synchronous processing interface to execute the MAC verification.
      operation MacVerify: possible-error=[CsmSha256HmacVerify_CsmMacVerifyConfig/CSM_E_BUSY, CsmSha256HmacVerify_CsmMacVerifyConfig/CSM_E_KEY_EMPTY, CsmSha256HmacVerify_CsmMacVerifyConfig/CSM_E_KEY_NOT_VALID, CsmSha256HmacVerify_CsmMacVerifyConfig/CSM_E_KEY_SIZE_MISMATCH, CsmSha256HmacVerify_CsmMacVerifyConfig/CSM_E_SMALL_BUFFER, CsmSha256HmacVerify_CsmMacVerifyConfig/E_NOT_OK, CsmSha256HmacVerify_CsmMacVerifyConfig/E_OK]  # Uses the given data to perform a MAC generation and stores the MAC in the memory location pointed to by the MAC pointer.
        6 x arg:
          mode: type=Crypto_OperationModeType, direction=IN  # indicates which operation mode(s) to perform
          dataBuffer: type=Csm_ConstDataPtr, direction=IN  # Contains the data from which a MAC shall be generated of.
          dataLength: type=uint32, direction=IN  # Contains the length in bytes of the data for whichs MAC shall be verified.
          compareBuffer: type=Csm_ConstDataPtr, direction=IN  # Contains the MAC to be verified.
          compareLength: type=uint32, direction=IN  # Contains the length in BITS of the MAC to be verified.
          resultBuffer: type=Crypto_VerifyResultType, direction=OUT  # Contains the verification result.
      7 x error:
        CSM_E_BUSY: error-code=2  # Request failed, service is still busy.
        CSM_E_KEY_EMPTY: error-code=13  # The service request failed because of uninitialized source key element.
        CSM_E_KEY_NOT_VALID: error-code=9  # Request failed, the key is not valid.
        CSM_E_KEY_SIZE_MISMATCH: error-code=10  # Request failed because the key element is not partially accessible and the provided key element length is too short or too long for that key element.
        CSM_E_SMALL_BUFFER: error-code=3  # The provided buffer is too small to store the result.
        E_NOT_OK: error-code=1  # Operation failed
        E_OK: error-code=0  # Operation successful
    RandomGenerate_L9_CsmRandomGenerateConfig  # Synchronous processing interface to execute the random number generation.
      operation RandomGenerate: possible-error=[RandomGenerate_L9_CsmRandomGenerateConfig/CSM_E_BUSY, RandomGenerate_L9_CsmRandomGenerateConfig/CSM_E_ENTROPY_EXHAUSTION, RandomGenerate_L9_CsmRandomGenerateConfig/E_NOT_OK, RandomGenerate_L9_CsmRandomGenerateConfig/E_OK]  # Synchronous processing interface to execute the random number generation.
        arg resultBuffer: type=uint8, direction=OUT  # Contains the random number
        arg resultLength: type=uint32, direction=INOUT  # Contains the length in bytes of the data of random number.
      4 x error:
        CSM_E_BUSY: error-code=2  # Request failed, service is still busy.
        CSM_E_ENTROPY_EXHAUSTION: error-code=4  # Request failed, entropy of random number generator is exhausted.
        E_NOT_OK: error-code=1  # Operation failed
        E_OK: error-code=0  # Operation successful
package /Csm/CompuMethods
  compu method Csm_JobIdTypeValue: 0=CSM_RandomGenerate_L9, 1=CSM_Hash_Sha256_Async, 2=CSM_Hash_SHA256_Sync, 3=CSM_RNG_HSE_Sync, 4=CSM_EncryptAES_ECB_sync, 5=CSM_DecryptAES_ECB_sync, 6=CSM_Hash_Sha256_Fota, 7=CSM_SignatureVerify_RSASSA_PKCS1_v1_5_Fota, 8=CSM_Decr_AES_CTR_Job0_swlib_Fota, 9=CSM_Decr_AES_CTR_Job1_swlib_Fota, 10=CSM_MacVer_AES_CMAC_key, 11=CSM_MacGen_Sha256_HMAC_key, 12=CSM_MacVer_Sha256_HMAC_key
  compu method Csm_KeyIdTypeValue: 0=CSM_RandomSeed_L9, 1=CSM_Dummy, 2=CSM_PBKDF2_Source_Key, 3=CSM_PBKDF2_Target_Key, 4=CSM_PBKDF2_Extracted_Key, 5=CSM_PBKDF2_ExtractedKey, 6=CSM_PBKDF2_Encrypt_Key, 7=CSM_PBKDF2_Decrypt_Key, 8..17=CSM_PBKDF2_Source_Key_PSK0..CSM_PBKDF2_Source_Key_PSK9, 18=CSM_Hash_Dummy_Fota, 19=CSM_Pkcs1_Asims_Public_key, 20=CSM_Decr_AES_CTR_Key0_swlib_Fota, 21=CSM_Decr_AES_CTR_Key1_swlib_Fota, 22=CSM_MacVer_AES_CMAC_key, 23=CSM_MacGen_Sha256_HMAC_key, 24=CSM_MacVer_Sha256_HMAC_key
package /Csm/ImplementationDataTypes
  30 x impl type:
    Crypto_OperationModeType: category=VALUE, base-type=uint8, compu {0x01=CRYPTO_OPERATIONMODE_START, 0x02=CRYPTO_OPERATIONMODE_UPDATE, 0x03=CRYPTO_OPERATIONMODE_STREAMSTART, 0x04=CRYPTO_OPERATIONMODE_FINISH, 0x07=CRYPTO_OPERATIONMODE_SINGLECALL}, range raw 0x01..0x07
    Crypto_VerifyResultType: category=VALUE, base-type=uint8, compu {0x00=CRYPTO_E_VER_OK, 0x01=CRYPTO_E_VER_NOT_OK}, range raw 0x00..0x01
    Csm_ConstDataPtr: category=DATA_REFERENCE, sw-pointer-target-props={target-category=VALUE, base-type=uint8, sw-impl-policy=CONST}
    Csm_DataPtr: category=DATA_REFERENCE, sw-pointer-target-props={target-category=VALUE, base-type=uint8}
    Csm_DecryptDataType_Crypto_HSE: category=ARRAY
      element Csm_DecryptDataType: array-size=500, array-size-semantics=FIXED-SIZE, implementation-data-type=uint8
    Csm_DecryptResultType_Crypto_HSE: category=ARRAY
      element Csm_DecryptResultType: array-size=500, array-size-semantics=FIXED-SIZE, implementation-data-type=uint8
    Csm_EncryptDataType_Crypto_HSE: category=ARRAY
      element Csm_EncryptDataType: array-size=500, array-size-semantics=FIXED-SIZE, implementation-data-type=uint8
    Csm_EncryptResultType_Crypto_HSE: category=ARRAY
      element Csm_EncryptResultType: array-size=500, array-size-semantics=FIXED-SIZE, implementation-data-type=uint8
    Csm_HashDataType_Crypto_HSE: category=ARRAY
      element Csm_HashDataType: array-size=64, array-size-semantics=FIXED-SIZE, implementation-data-type=uint8
    Csm_HashDataType_Crypto_SW: category=ARRAY
      element Csm_HashDataType: array-size=65536, array-size-semantics=FIXED-SIZE, implementation-data-type=uint8
    Csm_HashResultType_Crypto_HSE: category=ARRAY
      element Csm_HashResultType: array-size=32, array-size-semantics=FIXED-SIZE, implementation-data-type=uint8
    Csm_HashResultType_Crypto_SW: category=ARRAY
      element Csm_HashResultType: array-size=32, array-size-semantics=FIXED-SIZE, implementation-data-type=uint8
    Csm_KeyDataType_Decr_AES_CTR_Key0_swlib_Fota: category=ARRAY
      element Csm_KeyDataType: array-size=16, array-size-semantics=FIXED-SIZE, implementation-data-type=uint8
    Csm_KeyDataType_Decr_AES_CTR_Key1_swlib_Fota: category=ARRAY
      element Csm_KeyDataType: array-size=16, array-size-semantics=FIXED-SIZE, implementation-data-type=uint8
    Csm_KeyDataType_Hash_Dummy_Fota: category=ARRAY
      element Csm_KeyDataType: array-size=32, array-size-semantics=FIXED-SIZE, implementation-data-type=uint8
    Csm_KeyDataType_MacVer_AES_CMAC_key: category=ARRAY
      element Csm_KeyDataType: array-size=16, array-size-semantics=FIXED-SIZE, implementation-data-type=uint8
    Csm_KeyDataType_Pkcs1_Asims_Public_key: category=ARRAY
      element Csm_KeyDataType: array-size=260, array-size-semantics=FIXED-SIZE, implementation-data-type=uint8
    Csm_KeyDataType_RandomSeed_L9: category=ARRAY
      element Csm_KeyDataType: array-size=4, array-size-semantics=FIXED-SIZE, implementation-data-type=uint8
    Csm_LengthPtr: category=DATA_REFERENCE, sw-pointer-target-props={target-category=TYPE_REFERENCE, implementation-data-type=uint32}
    Csm_MacGenerateDataType_Crypto_HSE: category=ARRAY
      element Csm_MacGenerateDataType: array-size=326656, array-size-semantics=FIXED-SIZE, implementation-data-type=uint8
    Csm_MacGenerateResultType_Crypto_HSE: category=ARRAY
      element Csm_MacGenerateResultType: array-size=32, array-size-semantics=FIXED-SIZE, implementation-data-type=uint8
    Csm_MacVerifyCompareType_Crypto_HSE: category=ARRAY
      element Csm_MacVerifyCompareType: array-size=32, array-size-semantics=FIXED-SIZE, implementation-data-type=uint8
    Csm_MacVerifyCompareType_Crypto_SW: category=ARRAY
      element Csm_MacVerifyCompareType: array-size=128, array-size-semantics=FIXED-SIZE, implementation-data-type=uint8
    Csm_MacVerifyDataType_Crypto_HSE: category=ARRAY
      element Csm_MacVerifyDataType: array-size=326656, array-size-semantics=FIXED-SIZE, implementation-data-type=uint8
    Csm_RandomGenerateResultType_Crypto_HSE: category=ARRAY
      element Csm_RandomGenerateResultType: array-size=16, array-size-semantics=FIXED-SIZE, implementation-data-type=uint8
    Csm_RandomGenerateResultType_Crypto_SW: category=ARRAY
      element Csm_RandomGenerateResultType: array-size=8, array-size-semantics=FIXED-SIZE, implementation-data-type=uint8
    Csm_ResultType: category=VALUE, base-type=uint8, compu {0x02=E_SMALL_BUFFER, 0x03=E_ENTROPY_EXHAUSTION, 0x04=E_KEY_READ_FAIL, 0x05=E_KEY_NOT_AVAILABLE, 0x06=E_KEY_NOT_VALID, 0x07=E_JOB_CANCELED, 0x00=E_OK, 0x01=E_NOT_OK, 0x08=E_KEY_EMPTY}, range raw 0x00..0x08
    Csm_SignatureVerifyCompareType_Crypto_SW: category=ARRAY
      element Csm_SignatureVerifyCompareType: array-size=256, array-size-semantics=FIXED-SIZE, implementation-data-type=uint8
    Csm_SignatureVerifyDataType_Crypto_SW: category=ARRAY
      element Csm_SignatureVerifyDataType: array-size=256, array-size-semantics=FIXED-SIZE, implementation-data-type=uint8
    Csm_VerifyResultPtr: category=DATA_REFERENCE, sw-pointer-target-props={target-category=TYPE_REFERENCE, implementation-data-type=Crypto_VerifyResultType}
package /Csm/ServiceSwComponentTypes
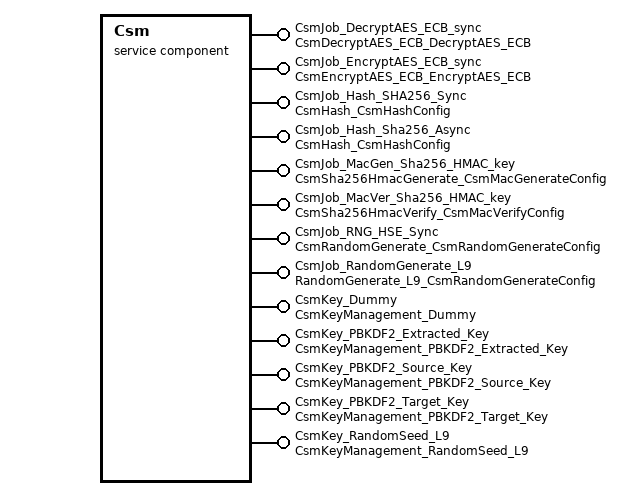
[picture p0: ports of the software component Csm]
  service sw component type Csm
    13 x provide port:
      CsmJob_DecryptAES_ECB_sync: server-com-spec{operation=Decrypt, queue-length=1}, provided-interface=CsmDecryptAES_ECB_DecryptAES_ECB  # Port related to a specific cryptographic job to execute the assigned cryptographic calculations synchronously.
      CsmJob_EncryptAES_ECB_sync: server-com-spec{operation=Encrypt, queue-length=1}, provided-interface=CsmEncryptAES_ECB_EncryptAES_ECB  # Port related to a specific cryptographic job to execute the assigned cryptographic calculations synchronously.
      CsmJob_Hash_SHA256_Sync: server-com-spec{operation=Hash, queue-length=1}, provided-interface=CsmHash_CsmHashConfig  # Port related to a specific cryptographic job to execute the assigned cryptographic calculations synchronously.
      CsmJob_Hash_Sha256_Async: server-com-spec{operation=Hash, queue-length=1}, provided-interface=CsmHash_CsmHashConfig  # Port related to a specific cryptographic job to execute the assigned cryptographic calculations synchronously.
      CsmJob_MacGen_Sha256_HMAC_key: server-com-spec{operation=MacGenerate, queue-length=1}, provided-interface=CsmSha256HmacGenerate_CsmMacGenerateConfig  # Port related to a specific cryptographic job to execute the assigned cryptographic calculations synchronously.
      CsmJob_MacVer_Sha256_HMAC_key: server-com-spec{operation=MacVerify, queue-length=1}, provided-interface=CsmSha256HmacVerify_CsmMacVerifyConfig  # Port related to a specific cryptographic job to execute the assigned cryptographic calculations synchronously.
      CsmJob_RNG_HSE_Sync: server-com-spec{operation=CsmRandomGenerate_CsmRandomGenerateConfig/RandomGenerate, queue-length=1}, provided-interface=CsmRandomGenerate_CsmRandomGenerateConfig  # Port related to a specific cryptographic job to execute the assigned cryptographic calculations synchronously.
      CsmJob_RandomGenerate_L9: server-com-spec{operation=RandomGenerate_L9_CsmRandomGenerateConfig/RandomGenerate, queue-length=1}, provided-interface=RandomGenerate_L9_CsmRandomGenerateConfig  # Port related to a specific cryptographic job to execute the assigned cryptographic calculations synchronously.
      CsmKey_Dummy: provided-interface=CsmKeyManagement_Dummy  # Port related to a specific cryptographic key to execute the key management functions synchronously.
        provided-com-specs:
          operation=CsmKeyManagement_Dummy/KeyCopy, queue-length=1
          operation=CsmKeyManagement_Dummy/KeyDerive, queue-length=1
          operation=CsmKeyManagement_Dummy/KeyElementCopy, queue-length=1
          operation=CsmKeyManagement_Dummy/KeyElementCopyPartial, queue-length=1
          operation=CsmKeyManagement_Dummy/KeyElementGet, queue-length=1
          operation=CsmKeyManagement_Dummy/KeyElementSet, queue-length=1
          operation=CsmKeyManagement_Dummy/KeyExchangeCalcPubVal, queue-length=1
          operation=CsmKeyManagement_Dummy/KeyExchangeCalcSecret, queue-length=1
          operation=CsmKeyManagement_Dummy/KeyGenerate, queue-length=1
          operation=CsmKeyManagement_Dummy/KeySetValid, queue-length=1
          operation=CsmKeyManagement_Dummy/RandomSeed, queue-length=1
      CsmKey_PBKDF2_Extracted_Key: provided-interface=CsmKeyManagement_PBKDF2_Extracted_Key  # Port related to a specific cryptographic key to execute the key management functions synchronously.
        provided-com-specs:
          operation=CsmKeyManagement_PBKDF2_Extracted_Key/KeyCopy, queue-length=1
          operation=CsmKeyManagement_PBKDF2_Extracted_Key/KeyDerive, queue-length=1
          operation=CsmKeyManagement_PBKDF2_Extracted_Key/KeyElementCopy, queue-length=1
          operation=CsmKeyManagement_PBKDF2_Extracted_Key/KeyElementCopyPartial, queue-length=1
          operation=CsmKeyManagement_PBKDF2_Extracted_Key/KeyElementGet, queue-length=1
          operation=CsmKeyManagement_PBKDF2_Extracted_Key/KeyElementSet, queue-length=1
          operation=CsmKeyManagement_PBKDF2_Extracted_Key/KeyExchangeCalcPubVal, queue-length=1
          operation=CsmKeyManagement_PBKDF2_Extracted_Key/KeyExchangeCalcSecret, queue-length=1
          operation=CsmKeyManagement_PBKDF2_Extracted_Key/KeyGenerate, queue-length=1
          operation=CsmKeyManagement_PBKDF2_Extracted_Key/KeySetValid, queue-length=1
          operation=CsmKeyManagement_PBKDF2_Extracted_Key/RandomSeed, queue-length=1
      CsmKey_PBKDF2_Source_Key: provided-interface=CsmKeyManagement_PBKDF2_Source_Key  # Port related to a specific cryptographic key to execute the key management functions synchronously.
        provided-com-specs:
          operation=CsmKeyManagement_PBKDF2_Source_Key/KeyCopy, queue-length=1
          operation=CsmKeyManagement_PBKDF2_Source_Key/KeyDerive, queue-length=1
          operation=CsmKeyManagement_PBKDF2_Source_Key/KeyElementCopy, queue-length=1
          operation=CsmKeyManagement_PBKDF2_Source_Key/KeyElementCopyPartial, queue-length=1
          operation=CsmKeyManagement_PBKDF2_Source_Key/KeyElementGet, queue-length=1
          operation=CsmKeyManagement_PBKDF2_Source_Key/KeyElementSet, queue-length=1
          operation=CsmKeyManagement_PBKDF2_Source_Key/KeyExchangeCalcPubVal, queue-length=1
          operation=CsmKeyManagement_PBKDF2_Source_Key/KeyExchangeCalcSecret, queue-length=1
          operation=CsmKeyManagement_PBKDF2_Source_Key/KeyGenerate, queue-length=1
          operation=CsmKeyManagement_PBKDF2_Source_Key/KeySetValid, queue-length=1
          operation=CsmKeyManagement_PBKDF2_Source_Key/RandomSeed, queue-length=1
      CsmKey_PBKDF2_Target_Key: provided-interface=CsmKeyManagement_PBKDF2_Target_Key  # Port related to a specific cryptographic key to execute the key management functions synchronously.
        provided-com-specs:
          operation=CsmKeyManagement_PBKDF2_Target_Key/KeyCopy, queue-length=1
          operation=CsmKeyManagement_PBKDF2_Target_Key/KeyDerive, queue-length=1
          operation=CsmKeyManagement_PBKDF2_Target_Key/KeyElementCopy, queue-length=1
          operation=CsmKeyManagement_PBKDF2_Target_Key/KeyElementCopyPartial, queue-length=1
          operation=CsmKeyManagement_PBKDF2_Target_Key/KeyElementGet, queue-length=1
          operation=CsmKeyManagement_PBKDF2_Target_Key/KeyElementSet, queue-length=1
          operation=CsmKeyManagement_PBKDF2_Target_Key/KeyExchangeCalcPubVal, queue-length=1
          operation=CsmKeyManagement_PBKDF2_Target_Key/KeyExchangeCalcSecret, queue-length=1
          operation=CsmKeyManagement_PBKDF2_Target_Key/KeyGenerate, queue-length=1
          operation=CsmKeyManagement_PBKDF2_Target_Key/KeySetValid, queue-length=1
          operation=CsmKeyManagement_PBKDF2_Target_Key/RandomSeed, queue-length=1
      CsmKey_RandomSeed_L9: provided-interface=CsmKeyManagement_RandomSeed_L9  # Port related to a specific cryptographic key to execute the key management functions synchronously.
        provided-com-specs:
          operation=CsmKeyManagement_RandomSeed_L9/KeyCopy, queue-length=1
          operation=CsmKeyManagement_RandomSeed_L9/KeyDerive, queue-length=1
          operation=CsmKeyManagement_RandomSeed_L9/KeyElementCopy, queue-length=1
          operation=CsmKeyManagement_RandomSeed_L9/KeyElementCopyPartial, queue-length=1
          operation=CsmKeyManagement_RandomSeed_L9/KeyElementGet, queue-length=1
          operation=CsmKeyManagement_RandomSeed_L9/KeyElementSet, queue-length=1
          operation=CsmKeyManagement_RandomSeed_L9/KeyExchangeCalcPubVal, queue-length=1
          operation=CsmKeyManagement_RandomSeed_L9/KeyExchangeCalcSecret, queue-length=1
          operation=CsmKeyManagement_RandomSeed_L9/KeyGenerate, queue-length=1
          operation=CsmKeyManagement_RandomSeed_L9/KeySetValid, queue-length=1
          operation=CsmKeyManagement_RandomSeed_L9/RandomSeed, queue-length=1
    behavior CsmInternalBehavior: handle-termination-and-restart=NO-SUPPORT, included-data-type-sets=[data-type=Crypto_OperationModeType, data-type=Crypto_VerifyResultType, data-type=Csm_ResultType]
      63 x operation invoked event:
        OperationInvokedEvent_CsmJob_DecryptAES_ECB_sync_Decrypt: start-on-event=Decrypt, operation=CsmJob_DecryptAES_ECB_sync.Decrypt
        OperationInvokedEvent_CsmJob_EncryptAES_ECB_sync_Encrypt: start-on-event=Encrypt, operation=CsmJob_EncryptAES_ECB_sync.Encrypt
        OperationInvokedEvent_CsmJob_Hash_SHA256_Sync_Hash: start-on-event=Hash, operation=CsmJob_Hash_SHA256_Sync.Hash
        OperationInvokedEvent_CsmJob_Hash_Sha256_Async_Hash: start-on-event=Hash, operation=CsmJob_Hash_Sha256_Async.Hash
        OperationInvokedEvent_CsmJob_MacGen_Sha256_HMAC_key_MacGenerate: start-on-event=MacGenerate, operation=CsmJob_MacGen_Sha256_HMAC_key.MacGenerate
        OperationInvokedEvent_CsmJob_MacVer_Sha256_HMAC_key_MacVerify: start-on-event=MacVerify, operation=CsmJob_MacVer_Sha256_HMAC_key.MacVerify
        OperationInvokedEvent_CsmJob_RNG_HSE_Sync_RandomGenerate: start-on-event=RandomGenerate, operation=CsmJob_RNG_HSE_Sync.RandomGenerate
        OperationInvokedEvent_CsmJob_RandomGenerate_L9_RandomGenerate: start-on-event=RandomGenerate, operation=CsmJob_RandomGenerate_L9.RandomGenerate
        OperationInvokedEvent_CsmKey_Dummy_KeyCopy: start-on-event=KeyCopy, operation=CsmKey_Dummy.KeyCopy
        OperationInvokedEvent_CsmKey_Dummy_KeyDerive: start-on-event=KeyDerive, operation=CsmKey_Dummy.KeyDerive
        OperationInvokedEvent_CsmKey_Dummy_KeyElementCopy: start-on-event=KeyElementCopy, operation=CsmKey_Dummy.KeyElementCopy
        OperationInvokedEvent_CsmKey_Dummy_KeyElementCopyPartial: start-on-event=KeyElementCopyPartial, operation=CsmKey_Dummy.KeyElementCopyPartial
        OperationInvokedEvent_CsmKey_Dummy_KeyElementGet: start-on-event=KeyElementGet, operation=CsmKey_Dummy.KeyElementGet
        OperationInvokedEvent_CsmKey_Dummy_KeyElementSet: start-on-event=KeyElementSet, operation=CsmKey_Dummy.KeyElementSet
        OperationInvokedEvent_CsmKey_Dummy_KeyExchangeCalcPubVal: start-on-event=KeyExchangeCalcPubVal, operation=CsmKey_Dummy.KeyExchangeCalcPubVal
        OperationInvokedEvent_CsmKey_Dummy_KeyExchangeCalcSecret: start-on-event=KeyExchangeCalcSecret, operation=CsmKey_Dummy.KeyExchangeCalcSecret
        OperationInvokedEvent_CsmKey_Dummy_KeyGenerate: start-on-event=KeyGenerate, operation=CsmKey_Dummy.KeyGenerate
        OperationInvokedEvent_CsmKey_Dummy_KeySetValid: start-on-event=KeySetValid, operation=CsmKey_Dummy.KeySetValid
        OperationInvokedEvent_CsmKey_Dummy_RandomSeed: start-on-event=RandomSeed, operation=CsmKey_Dummy.RandomSeed
        OperationInvokedEvent_CsmKey_PBKDF2_Extracted_Key_KeyCopy: start-on-event=KeyCopy, operation=CsmKey_PBKDF2_Extracted_Key.KeyCopy
        OperationInvokedEvent_CsmKey_PBKDF2_Extracted_Key_KeyDerive: start-on-event=KeyDerive, operation=CsmKey_PBKDF2_Extracted_Key.KeyDerive
        OperationInvokedEvent_CsmKey_PBKDF2_Extracted_Key_KeyElementCopy: start-on-event=KeyElementCopy, operation=CsmKey_PBKDF2_Extracted_Key.KeyElementCopy
        OperationInvokedEvent_CsmKey_PBKDF2_Extracted_Key_KeyElementCopyPartial: start-on-event=KeyElementCopyPartial, operation=CsmKey_PBKDF2_Extracted_Key.KeyElementCopyPartial
        OperationInvokedEvent_CsmKey_PBKDF2_Extracted_Key_KeyElementGet: start-on-event=KeyElementGet, operation=CsmKey_PBKDF2_Extracted_Key.KeyElementGet
        OperationInvokedEvent_CsmKey_PBKDF2_Extracted_Key_KeyElementSet: start-on-event=KeyElementSet, operation=CsmKey_PBKDF2_Extracted_Key.KeyElementSet
        OperationInvokedEvent_CsmKey_PBKDF2_Extracted_Key_KeyExchangeCalcPubVal: start-on-event=KeyExchangeCalcPubVal, operation=CsmKey_PBKDF2_Extracted_Key.KeyExchangeCalcPubVal
        OperationInvokedEvent_CsmKey_PBKDF2_Extracted_Key_KeyExchangeCalcSecret: start-on-event=KeyExchangeCalcSecret, operation=CsmKey_PBKDF2_Extracted_Key.KeyExchangeCalcSecret
        OperationInvokedEvent_CsmKey_PBKDF2_Extracted_Key_KeyGenerate: start-on-event=KeyGenerate, operation=CsmKey_PBKDF2_Extracted_Key.KeyGenerate
        OperationInvokedEvent_CsmKey_PBKDF2_Extracted_Key_KeySetValid: start-on-event=KeySetValid, operation=CsmKey_PBKDF2_Extracted_Key.KeySetValid
        OperationInvokedEvent_CsmKey_PBKDF2_Extracted_Key_RandomSeed: start-on-event=RandomSeed, operation=CsmKey_PBKDF2_Extracted_Key.RandomSeed
        OperationInvokedEvent_CsmKey_PBKDF2_Source_Key_KeyCopy: start-on-event=KeyCopy, operation=CsmKey_PBKDF2_Source_Key.KeyCopy
        OperationInvokedEvent_CsmKey_PBKDF2_Source_Key_KeyDerive: start-on-event=KeyDerive, operation=CsmKey_PBKDF2_Source_Key.KeyDerive
        OperationInvokedEvent_CsmKey_PBKDF2_Source_Key_KeyElementCopy: start-on-event=KeyElementCopy, operation=CsmKey_PBKDF2_Source_Key.KeyElementCopy
        OperationInvokedEvent_CsmKey_PBKDF2_Source_Key_KeyElementCopyPartial: start-on-event=KeyElementCopyPartial, operation=CsmKey_PBKDF2_Source_Key.KeyElementCopyPartial
        OperationInvokedEvent_CsmKey_PBKDF2_Source_Key_KeyElementGet: start-on-event=KeyElementGet, operation=CsmKey_PBKDF2_Source_Key.KeyElementGet
        OperationInvokedEvent_CsmKey_PBKDF2_Source_Key_KeyElementSet: start-on-event=KeyElementSet, operation=CsmKey_PBKDF2_Source_Key.KeyElementSet
        OperationInvokedEvent_CsmKey_PBKDF2_Source_Key_KeyExchangeCalcPubVal: start-on-event=KeyExchangeCalcPubVal, operation=CsmKey_PBKDF2_Source_Key.KeyExchangeCalcPubVal
        OperationInvokedEvent_CsmKey_PBKDF2_Source_Key_KeyExchangeCalcSecret: start-on-event=KeyExchangeCalcSecret, operation=CsmKey_PBKDF2_Source_Key.KeyExchangeCalcSecret
        OperationInvokedEvent_CsmKey_PBKDF2_Source_Key_KeyGenerate: start-on-event=KeyGenerate, operation=CsmKey_PBKDF2_Source_Key.KeyGenerate
        OperationInvokedEvent_CsmKey_PBKDF2_Source_Key_KeySetValid: start-on-event=KeySetValid, operation=CsmKey_PBKDF2_Source_Key.KeySetValid
        OperationInvokedEvent_CsmKey_PBKDF2_Source_Key_RandomSeed: start-on-event=RandomSeed, operation=CsmKey_PBKDF2_Source_Key.RandomSeed
        OperationInvokedEvent_CsmKey_PBKDF2_Target_Key_KeyCopy: start-on-event=KeyCopy, operation=CsmKey_PBKDF2_Target_Key.KeyCopy
        OperationInvokedEvent_CsmKey_PBKDF2_Target_Key_KeyDerive: start-on-event=KeyDerive, operation=CsmKey_PBKDF2_Target_Key.KeyDerive
        OperationInvokedEvent_CsmKey_PBKDF2_Target_Key_KeyElementCopy: start-on-event=KeyElementCopy, operation=CsmKey_PBKDF2_Target_Key.KeyElementCopy
        OperationInvokedEvent_CsmKey_PBKDF2_Target_Key_KeyElementCopyPartial: start-on-event=KeyElementCopyPartial, operation=CsmKey_PBKDF2_Target_Key.KeyElementCopyPartial
        OperationInvokedEvent_CsmKey_PBKDF2_Target_Key_KeyElementGet: start-on-event=KeyElementGet, operation=CsmKey_PBKDF2_Target_Key.KeyElementGet
        OperationInvokedEvent_CsmKey_PBKDF2_Target_Key_KeyElementSet: start-on-event=KeyElementSet, operation=CsmKey_PBKDF2_Target_Key.KeyElementSet
        OperationInvokedEvent_CsmKey_PBKDF2_Target_Key_KeyExchangeCalcPubVal: start-on-event=KeyExchangeCalcPubVal, operation=CsmKey_PBKDF2_Target_Key.KeyExchangeCalcPubVal
        OperationInvokedEvent_CsmKey_PBKDF2_Target_Key_KeyExchangeCalcSecret: start-on-event=KeyExchangeCalcSecret, operation=CsmKey_PBKDF2_Target_Key.KeyExchangeCalcSecret
        OperationInvokedEvent_CsmKey_PBKDF2_Target_Key_KeyGenerate: start-on-event=KeyGenerate, operation=CsmKey_PBKDF2_Target_Key.KeyGenerate
        OperationInvokedEvent_CsmKey_PBKDF2_Target_Key_KeySetValid: start-on-event=KeySetValid, operation=CsmKey_PBKDF2_Target_Key.KeySetValid
        OperationInvokedEvent_CsmKey_PBKDF2_Target_Key_RandomSeed: start-on-event=RandomSeed, operation=CsmKey_PBKDF2_Target_Key.RandomSeed
        OperationInvokedEvent_CsmKey_RandomSeed_L9_KeyCopy: start-on-event=KeyCopy, operation=CsmKey_RandomSeed_L9.KeyCopy
        OperationInvokedEvent_CsmKey_RandomSeed_L9_KeyDerive: start-on-event=KeyDerive, operation=CsmKey_RandomSeed_L9.KeyDerive
        OperationInvokedEvent_CsmKey_RandomSeed_L9_KeyElementCopy: start-on-event=KeyElementCopy, operation=CsmKey_RandomSeed_L9.KeyElementCopy
        OperationInvokedEvent_CsmKey_RandomSeed_L9_KeyElementCopyPartial: start-on-event=KeyElementCopyPartial, operation=CsmKey_RandomSeed_L9.KeyElementCopyPartial
        OperationInvokedEvent_CsmKey_RandomSeed_L9_KeyElementGet: start-on-event=KeyElementGet, operation=CsmKey_RandomSeed_L9.KeyElementGet
        OperationInvokedEvent_CsmKey_RandomSeed_L9_KeyElementSet: start-on-event=KeyElementSet, operation=CsmKey_RandomSeed_L9.KeyElementSet
        OperationInvokedEvent_CsmKey_RandomSeed_L9_KeyExchangeCalcPubVal: start-on-event=KeyExchangeCalcPubVal, operation=CsmKey_RandomSeed_L9.KeyExchangeCalcPubVal
        OperationInvokedEvent_CsmKey_RandomSeed_L9_KeyExchangeCalcSecret: start-on-event=KeyExchangeCalcSecret, operation=CsmKey_RandomSeed_L9.KeyExchangeCalcSecret
        OperationInvokedEvent_CsmKey_RandomSeed_L9_KeyGenerate: start-on-event=KeyGenerate, operation=CsmKey_RandomSeed_L9.KeyGenerate
        OperationInvokedEvent_CsmKey_RandomSeed_L9_KeySetValid: start-on-event=KeySetValid, operation=CsmKey_RandomSeed_L9.KeySetValid
        OperationInvokedEvent_CsmKey_RandomSeed_L9_RandomSeed: start-on-event=RandomSeed, operation=CsmKey_RandomSeed_L9.RandomSeed
      port-api-options:
        {enable-take-address=false, indirect-api=false, port-defined-argument-value{value=0, value-type=uint32}, port=CsmJob_RandomGenerate_L9}
        {enable-take-address=false, indirect-api=false, port-defined-argument-value{value=1, value-type=uint32}, port=CsmJob_Hash_Sha256_Async}
        {enable-take-address=false, indirect-api=false, port-defined-argument-value{value=2, value-type=uint32}, port=CsmJob_Hash_SHA256_Sync}
        {enable-take-address=false, indirect-api=false, port-defined-argument-value{value=3, value-type=uint32}, port=CsmJob_RNG_HSE_Sync}
        {enable-take-address=false, indirect-api=false, port-defined-argument-value{value=4, value-type=uint32}, port=CsmJob_EncryptAES_ECB_sync}
        {enable-take-address=false, indirect-api=false, port-defined-argument-value{value=5, value-type=uint32}, port=CsmJob_DecryptAES_ECB_sync}
        {enable-take-address=false, indirect-api=false, port-defined-argument-value{value=11, value-type=uint32}, port=CsmJob_MacGen_Sha256_HMAC_key}
        {enable-take-address=false, indirect-api=false, port-defined-argument-value{value=12, value-type=uint32}, port=CsmJob_MacVer_Sha256_HMAC_key}
        {enable-take-address=false, indirect-api=false, port-defined-argument-value{value=0, value-type=uint32}, port=CsmKey_RandomSeed_L9}
        {enable-take-address=false, indirect-api=false, port-defined-argument-value{value=1, value-type=uint32}, port=CsmKey_Dummy}
        {enable-take-address=false, indirect-api=false, port-defined-argument-value{value=2, value-type=uint32}, port=CsmKey_PBKDF2_Source_Key}
        {enable-take-address=false, indirect-api=false, port-defined-argument-value{value=3, value-type=uint32}, port=CsmKey_PBKDF2_Target_Key}
        {enable-take-address=false, indirect-api=false, port-defined-argument-value{value=4, value-type=uint32}, port=CsmKey_PBKDF2_Extracted_Key}
      18 x runnable:
        Decrypt: can-be-invoked-concurrently=true, symbol=Csm_Decrypt
        Encrypt: can-be-invoked-concurrently=true, symbol=Csm_Encrypt
        Hash: can-be-invoked-concurrently=true, symbol=Csm_Hash
        KeyCopy: can-be-invoked-concurrently=true, symbol=Csm_KeyCopy
        KeyDerive: can-be-invoked-concurrently=true, symbol=Csm_KeyDerive
        KeyElementCopy: can-be-invoked-concurrently=true, symbol=Csm_KeyElementCopy
        KeyElementCopyPartial: can-be-invoked-concurrently=true, symbol=Csm_KeyElementCopyPartial
        KeyElementGet: can-be-invoked-concurrently=true, symbol=Csm_KeyElementGet
        KeyElementSet: symbol=Csm_KeyElementSet
        KeyExchangeCalcPubVal: can-be-invoked-concurrently=true, symbol=Csm_KeyExchangeCalcPubVal
        KeyExchangeCalcSecret: can-be-invoked-concurrently=true, symbol=Csm_KeyExchangeCalcSecret
        KeyGenerate: can-be-invoked-concurrently=true, symbol=Csm_KeyGenerate
        KeySetValid: symbol=Csm_KeySetValid
        MacGenerate: can-be-invoked-concurrently=true, symbol=Csm_MacGenerate
        MacVerify: can-be-invoked-concurrently=true, symbol=Csm_MacVerify
        MainFunction: symbol=Csm_MainFunction
        RandomGenerate: can-be-invoked-concurrently=true, symbol=Csm_RandomGenerate
        RandomSeed: can-be-invoked-concurrently=true, symbol=Csm_RandomSeed
  swc bsw mapping SwcBswMapping_Csm: bsw-behavior=BswInternalBehavior_Csm, swc-behavior=CsmInternalBehavior
    runnable-mappings:
      bsw-entity=BswCE_Csm_KeyElementSet, swc-runnable=KeyElementSet
      bsw-entity=BswCE_Csm_KeySetValid, swc-runnable=KeySetValid
      bsw-entity=BswCE_Csm_KeyElementGet, swc-runnable=KeyElementGet
      bsw-entity=BswCE_Csm_KeyElementCopy, swc-runnable=KeyElementCopy
      bsw-entity=BswCE_Csm_KeyCopy, swc-runnable=KeyCopy
      bsw-entity=BswCE_Csm_KeyElementCopyPartial, swc-runnable=KeyElementCopyPartial
      bsw-entity=BswCE_Csm_RandomSeed, swc-runnable=RandomSeed
      bsw-entity=BswCE_Csm_KeyGenerate, swc-runnable=KeyGenerate
      bsw-entity=BswCE_Csm_KeyDerive, swc-runnable=KeyDerive
      bsw-entity=BswCE_Csm_KeyExchangeCalcPubVal, swc-runnable=KeyExchangeCalcPubVal
      bsw-entity=BswCE_Csm_KeyExchangeCalcSecret, swc-runnable=KeyExchangeCalcSecret
      bsw-entity=BswCE_Csm_RandomGenerate, swc-runnable=RandomGenerate
      bsw-entity=BswCE_Csm_MacGenerate, swc-runnable=MacGenerate
      bsw-entity=BswCE_Csm_Decrypt, swc-runnable=Decrypt
      bsw-entity=BswCE_Csm_Hash, swc-runnable=Hash
      bsw-entity=BswCE_Csm_MacVerify, swc-runnable=MacVerify
      bsw-entity=BswCE_Csm_Encrypt, swc-runnable=Encrypt
      bsw-entity=BswSE_Csm_MainFunction, swc-runnable=MainFunction
  swc implementation SwcImplementation_Csm: swc-bsw-mapping=SwcBswMapping_Csm, behavior=CsmInternalBehavior
